VERSION ""

NS_ :

BS_:

BU_: RADAR VEHICLE ACC ACCM

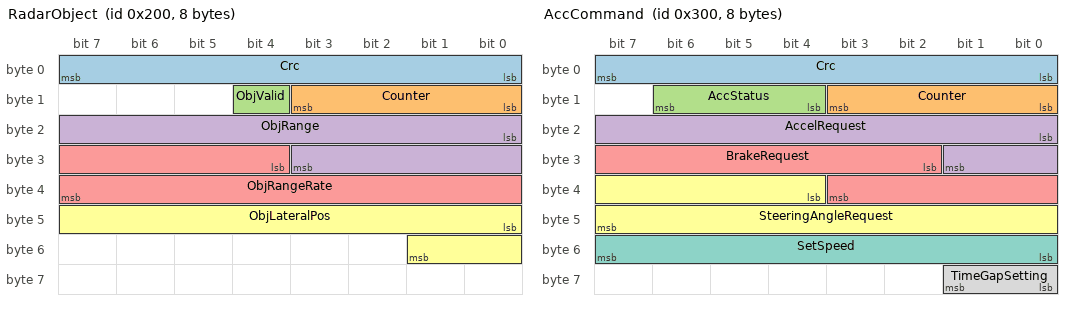
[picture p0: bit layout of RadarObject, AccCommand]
BO_ 512 RadarObject: 8 RADAR
 SG_ Crc : 0|8@1+ (1,0) [0|255] "" ACC
 SG_ Counter : 8|4@1+ (1,0) [0|15] "" ACC
 SG_ ObjValid : 12|1@1+ (1,0) [0|1] "" ACC
 SG_ ObjRange : 16|12@1+ (0.1,0) [0|409.5] "m" ACC
 SG_ ObjRangeRate : 28|12@1- (0.05,0) [-102.4|102.35] "m/s" ACC
 SG_ ObjLateralPos : 40|10@1- (0.02,0) [-10.24|10.22] "m" ACC

BO_ 768 AccCommand: 8 ACC
 SG_ Crc : 0|8@1+ (1,0) [0|255] "" VEHICLE
 SG_ Counter : 8|4@1+ (1,0) [0|15] "" VEHICLE
 SG_ AccStatus : 12|3@1+ (1,0) [0|4] "" VEHICLE
 SG_ AccelRequest : 16|10@1+ (0.01,0) [0|5] "m/s2" VEHICLE
 SG_ BrakeRequest : 26|10@1+ (0.01,0) [0|10] "m/s2" VEHICLE
 SG_ SteeringAngleRequest : 36|12@1- (0.1,0) [-180|180] "deg" VEHICLE
 SG_ SetSpeed : 48|8@1+ (1,0) [0|250] "km/h" VEHICLE
 SG_ TimeGapSetting : 56|2@1+ (1,0) [0|3] "" VEHICLE

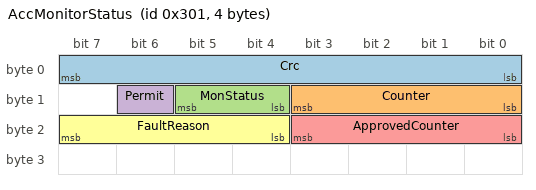
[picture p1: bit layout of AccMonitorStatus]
BO_ 769 AccMonitorStatus: 4 ACCM
 SG_ Crc : 0|8@1+ (1,0) [0|255] "" VEHICLE
 SG_ Counter : 8|4@1+ (1,0) [0|15] "" VEHICLE
 SG_ MonStatus : 12|2@1+ (1,0) [0|2] "" VEHICLE
 SG_ Permit : 14|1@1+ (1,0) [0|1] "" VEHICLE
 SG_ ApprovedCounter : 16|4@1+ (1,0) [0|15] "" VEHICLE
 SG_ FaultReason : 20|4@1+ (1,0) [0|15] "" VEHICLE

CM_ SG_ 768 AccStatus "0=OFF 1=STANDBY 2=ACTIVE 3=OVERRIDE 4=FAULT";
CM_ SG_ 769 MonStatus "0=INIT 1=MONITORING 2=SAFE_STATE";
CM_ SG_ 769 FaultReason "0=NONE 1=COMMAND_TIMEOUT 2=REQUEST_LIMIT 3=ACCEL_AND_BRAKE 4=REQUEST_OUTSIDE_ACTIVE 5=REQUEST_RATE 6=UNINTENDED_ACCEL";
